# STM32N657 register map
File version: 1.0
CPU: CM55 r0p1, little endian, no MPU, FPU, vendor SysTick, 8 interrupt priority bits
Registers are 32-bit, read-write, reset 0x0 unless marked. A register's access mark holds for its fields unless they carry their own. Offsets are from the block's base; [hi:lo] are bit positions; 'fields as' and 'values as' point back to an identical list.

## LPTIM1 — Low-power timer
Base 0x40002400
Same registers: LPTIM1_S 0x50002400
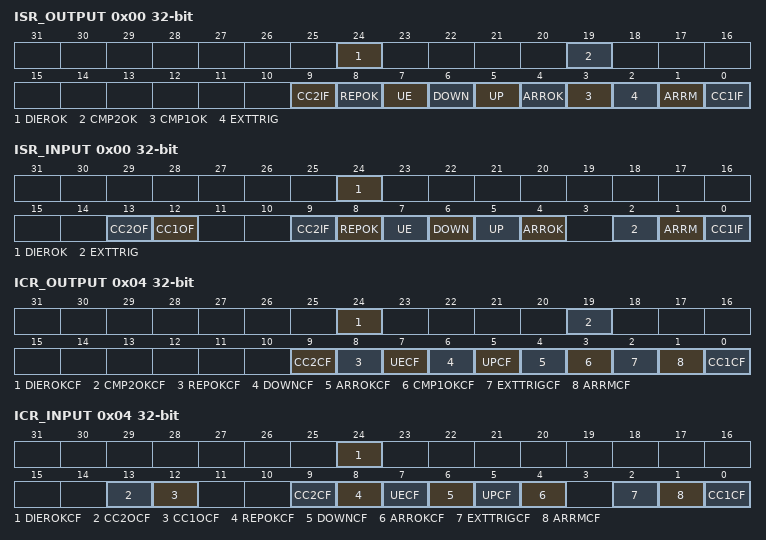
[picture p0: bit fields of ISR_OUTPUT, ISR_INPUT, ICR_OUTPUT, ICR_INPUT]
0x00 ISR_OUTPUT ro — LPTIM1 interrupt and status register [alternate]
  [24] DIEROK — Interrupt enable register update OK
  [19] CMP2OK — Compare register 2 update OK
  [9] CC2IF — Compare 2 interrupt flag
  [8] REPOK — Repetition register update OK
  [7] UE — LPTIM update event occurred
  [6] DOWN — Counter direction change up to down
  [5] UP — Counter direction change down to up
  [4] ARROK — Autoreload register update OK
  [3] CMP1OK — Compare register 1 update OK
  [2] EXTTRIG — External trigger edge event
  [1] ARRM — Autoreload match
  [0] CC1IF — Compare 1 interrupt flag
0x00 ISR_INPUT ro (alternate view of ISR_OUTPUT) — LPTIM1 interrupt and status register [alternate]
  [24] DIEROK — Interrupt enable register update OK
  [13] CC2OF — Capture 2 over-capture flag
  [12] CC1OF — Capture 1 over-capture flag
  [9] CC2IF — Capture 2 interrupt flag
  [8] REPOK — Repetition register update OK
  [7] UE — LPTIM update event occurred
  [6] DOWN — Counter direction change up to down
  [5] UP — Counter direction change down to up
  [4] ARROK — Autoreload register update OK
  [2] EXTTRIG — External trigger edge event
  [1] ARRM — Autoreload match
  [0] CC1IF — capture 1 interrupt flag
0x04 ICR_OUTPUT wo — LPTIM1 interrupt clear register [alternate]
  [24] DIEROKCF — Interrupt enable register update OK clear flag
  [19] CMP2OKCF — Compare register 2 update OK clear flag
  [9] CC2CF — Capture/compare 2 clear flag
  [8] REPOKCF — Repetition register update OK clear flag
  [7] UECF — Update event clear flag
  [6] DOWNCF — Direction change to down clear flag
  [5] UPCF — Direction change to UP clear flag
  [4] ARROKCF — Autoreload register update OK clear flag
  [3] CMP1OKCF — Compare register 1 update OK clear flag
  [2] EXTTRIGCF — External trigger valid edge clear flag
  [1] ARRMCF — Autoreload match clear flag
  [0] CC1CF — Capture/compare 1 clear flag
0x04 ICR_INPUT wo (alternate view of ICR_OUTPUT) — LPTIM1 interrupt clear register [alternate]
  [24] DIEROKCF — Interrupt enable register update OK clear flag
  [13] CC2OCF — Capture/compare 2 over-capture clear flag
  [12] CC1OCF — Capture/compare 1 over-capture clear flag
  [9] CC2CF — Capture/compare 2 clear flag
  [8] REPOKCF — Repetition register update OK clear flag
  [7] UECF — Update event clear flag
  [6] DOWNCF — Direction change to down clear flag
  [5] UPCF — Direction change to UP clear flag
  [4] ARROKCF — Autoreload register update OK clear flag
  [2] EXTTRIGCF — External trigger valid edge clear flag
  [1] ARRMCF — Autoreload match clear flag
  [0] CC1CF — Capture/compare 1 clear flag
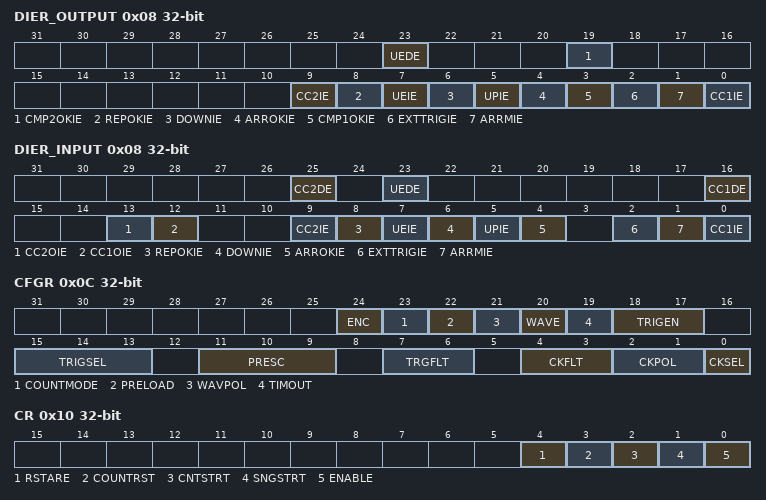
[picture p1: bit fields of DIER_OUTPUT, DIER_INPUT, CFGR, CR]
0x08 DIER_OUTPUT — LPTIM1 interrupt enable register [alternate]
  [23] UEDE — Update event DMA request enable
  [19] CMP2OKIE — Compare register 2 update OK interrupt enable
  [9] CC2IE — Capture/compare 2 interrupt enable
  [8] REPOKIE — Repetition register update OK interrupt Enable
  [7] UEIE — Update event interrupt enable
  [6] DOWNIE — Direction change to down Interrupt Enable
  [5] UPIE — Direction change to UP Interrupt Enable
  [4] ARROKIE — Autoreload register update OK Interrupt Enable
  [3] CMP1OKIE — Compare register 1 update OK interrupt enable
  [2] EXTTRIGIE — External trigger valid edge Interrupt Enable
  [1] ARRMIE — Autoreload match Interrupt Enable
  [0] CC1IE — Capture/compare 1 interrupt enable
0x08 DIER_INPUT (alternate view of DIER_OUTPUT) — LPTIM1 interrupt enable register [alternate]
  [25] CC2DE — Capture/compare 2 DMA request enable
  [23] UEDE — Update event DMA request enable
  [16] CC1DE — Capture/compare 1 DMA request enable
  [13] CC2OIE — Capture/compare 2 over-capture interrupt enable
  [12] CC1OIE — Capture/compare 1 over-capture interrupt enable
  [9] CC2IE — Capture/compare 2 interrupt enable
  [8] REPOKIE — Repetition register update OK interrupt Enable
  [7] UEIE — Update event interrupt enable
  [6] DOWNIE — Direction change to down Interrupt Enable
  [5] UPIE — Direction change to UP Interrupt Enable
  [4] ARROKIE — Autoreload register update OK Interrupt Enable
  [2] EXTTRIGIE — External trigger valid edge Interrupt Enable
  [1] ARRMIE — Autoreload match Interrupt Enable
  [0] CC1IE — Capture/compare 1 interrupt enable
0x0C CFGR — LPTIM1 configuration register
  [24] ENC — Encoder mode enable
  [23] COUNTMODE — counter mode enabled
  [22] PRELOAD — Registers update mode
  [21] WAVPOL — Waveform shape polarity
  [20] WAVE — Waveform shape
  [19] TIMOUT — Timeout enable
  [18:17] TRIGEN — Trigger enable and polarity
  [15:13] TRIGSEL — Trigger selector
  [11:9] PRESC — Clock prescaler
  [7:6] TRGFLT — Configurable digital filter for trigger
  [4:3] CKFLT — Configurable digital filter for external clock
  [2:1] CKPOL — Clock Polarity
  [0] CKSEL — Clock selector
0x10 CR — LPTIM1 control register
  [4] RSTARE — Reset after read enable
  [3] COUNTRST — Counter reset
  [2] CNTSTRT — Timer start in Continuous mode
  [1] SNGSTRT — LPTIM start in Single mode
  [0] ENABLE — LPTIM enable
0x14 CCR1 — LPTIM1 compare register 1
  [15:0] CCR1 — Capture/compare 1 value
0x18 ARR reset 0x1 — LPTIM1 autoreload register
  [15:0] ARR — Auto reload value
0x1C CNT ro — LPTIM1 counter register
  [15:0] CNT — Counter value
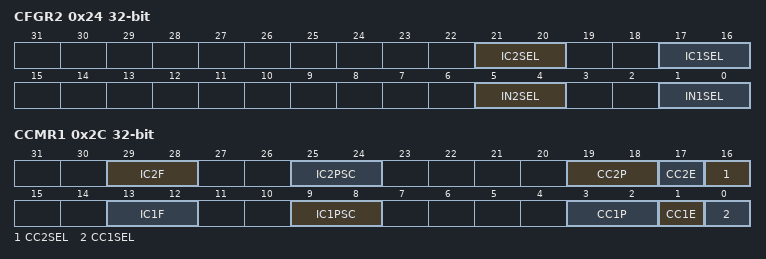
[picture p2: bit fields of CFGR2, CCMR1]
0x24 CFGR2 — LPTIM1 configuration register 2
  [21:20] IC2SEL — LPTIM input capture 2 selection
  [17:16] IC1SEL — LPTIM input capture 1 selection
  [5:4] IN2SEL — LPTIM input 2 selection
  [1:0] IN1SEL — LPTIM input 1 selection
0x28 RCR — LPTIM1 repetition register
  [7:0] REP — Repetition register value
0x2C CCMR1 — LPTIM1 capture/compare mode register 1
  [29:28] IC2F — Input capture 2 filter
  [25:24] IC2PSC — Input capture 2 prescaler
  [19:18] CC2P — Capture/compare 2 output polarity.
  [17] CC2E — Capture/compare 2 output enable.
  [16] CC2SEL — Capture/compare 2 selection
  [13:12] IC1F — Input capture 1 filter
  [9:8] IC1PSC — Input capture 1 prescaler
  [3:2] CC1P — Capture/compare 1 output polarity.
  [1] CC1E — Capture/compare 1 output enable.
  [0] CC1SEL — Capture/compare 1 selection
0x34 CCR2 — LPTIM1 compare register 2
  [15:0] CCR2 — Capture/compare 2 value

## LPTIM2 — Low-power timer
Base 0x46002400
Same registers: LPTIM2_S 0x56002400
Registers as LPTIM1 (with LPTIM1 read as LPTIM2); these are added or differ:
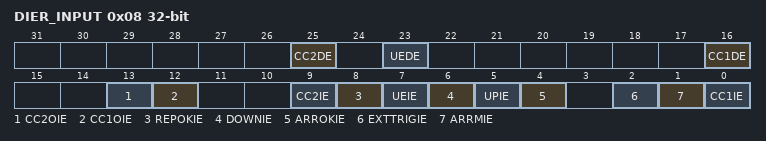
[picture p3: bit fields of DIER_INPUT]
0x08 DIER_INPUT (alternate view of DIER_OUTPUT) — LPTIM1 interrupt enable register [alternate]
  fields as LPTIM1.DIER_INPUT

## LPTIM3 — Low-power timer
Base 0x46002800
Same registers: LPTIM3_S 0x56002800
Registers as LPTIM1 (with LPTIM1 read as LPTIM3).

## LPTIM4 — Low-power timer
Base 0x46002C00
Same registers: LPTIM4_S 0x56002C00
Registers as LPTIM1 (with LPTIM1 read as LPTIM4), without ISR_OUTPUT, ISR_INPUT, ICR_OUTPUT, ICR_INPUT, DIER_OUTPUT, DIER_INPUT; these are added or differ:
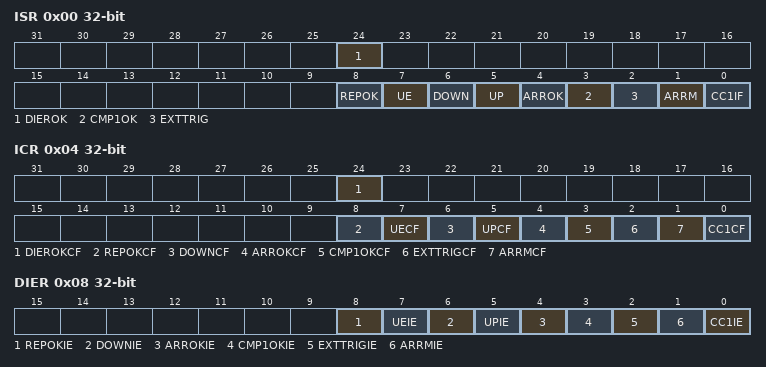
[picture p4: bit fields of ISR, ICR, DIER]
0x00 ISR ro — LPTIM4 interrupt and status register
  [24] DIEROK — Interrupt enable register update OK
  [8] REPOK — Repetition register update OK
  [7] UE — LPTIM update event occurred
  [6] DOWN — Counter direction change up to down
  [5] UP — Counter direction change down to up
  [4] ARROK — Autoreload register update OK
  [3] CMP1OK — Compare register 1 update OK
  [2] EXTTRIG — External trigger edge event
  [1] ARRM — Autoreload match
  [0] CC1IF — Compare 1 interrupt flag
0x04 ICR wo — LPTIM4 interrupt clear register
  [24] DIEROKCF — Interrupt enable register update OK clear flag
  [8] REPOKCF — Repetition register update OK clear flag
  [7] UECF — Update event clear flag
  [6] DOWNCF — Direction change to down clear flag
  [5] UPCF — Direction change to UP clear flag
  [4] ARROKCF — Autoreload register update OK clear flag
  [3] CMP1OKCF — Compare register 1 update OK clear flag
  [2] EXTTRIGCF — External trigger valid edge clear flag
  [1] ARRMCF — Autoreload match clear flag
  [0] CC1CF — Capture/compare 1 clear flag
0x08 DIER — LPTIM4 interrupt enable register
  [8] REPOKIE — Repetition register update OK interrupt Enable
  [7] UEIE — Update event interrupt enable
  [6] DOWNIE — Direction change to down Interrupt Enable
  [5] UPIE — Direction change to UP Interrupt Enable
  [4] ARROKIE — Autoreload register update OK Interrupt Enable
  [3] CMP1OKIE — Compare register 1 update OK interrupt enable
  [2] EXTTRIGIE — External trigger valid edge Interrupt Enable
  [1] ARRMIE — Autoreload match Interrupt Enable
  [0] CC1IE — Capture/compare 1 interrupt enable

## LPTIM5 — Low-power timer
Base 0x46003000
Same registers: LPTIM5_S 0x56003000
Registers as LPTIM4 (with LPTIM4 read as LPTIM5).
